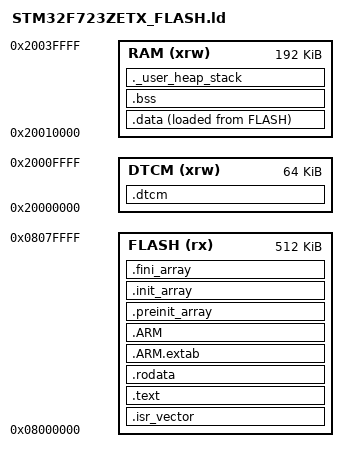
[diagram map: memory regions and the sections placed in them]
/*
******************************************************************************
**
** @file        : LinkerScript.ld
**
** @author      : Auto-generated by STM32CubeIDE
**
** @brief       : Linker script for STM32F723ZETx Device from STM32F7 series
**                      512KBytes FLASH
**                      256KBytes RAM
**
**                Set heap size, stack size and stack location according
**                to application requirements.
**
**                Set memory bank area and size if external memory is used
**
**  Target      : STMicroelectronics STM32
**
**  Distribution: The file is distributed as is, without any warranty
**                of any kind.
**
******************************************************************************
** @attention
**
** Copyright (c) 2026 STMicroelectronics.
** All rights reserved.
**
** This software is licensed under terms that can be found in the LICENSE file
** in the root directory of this software component.
** If no LICENSE file comes with this software, it is provided AS-IS.
**
******************************************************************************
*/

/* Entry Point */
ENTRY(Reset_Handler)

/* Highest address of the user mode stack */
_estack = ORIGIN(RAM) + LENGTH(RAM); /* end of "RAM" Ram type memory */

_Min_Heap_Size = 0x200;  /* required amount of heap  */
_Min_Stack_Size = 0x1000; /* required amount of stack */
/* Stack raised 0x400 -> 0x1000 (TN-16 open item 19). The console, the
   self-flasher and the coming logger all add call depth, and 1 KiB was
   already uncomfortable next to vsnprintf.

   REGENERATION HAZARD: CubeIDE rewrote this line back to 0x400 on 27 Jul 2026
   while leaving the MEMORY block and the .dtcm section intact. It templates
   the two size lines but not the rest of the script, so check this value
   after every regeneration. Added to the TN-17A section 8 checklist. */

/* Memories definition
 *
 * SPLIT FROM A SINGLE FLAT REGION, 27 July 2026. CubeMX generates one 256 KiB
 * block at 0x20000000, which silently places every .data and .bss object in
 * DTCM. Two problems follow, and both are fixed by declaring the split:
 *
 *   1. DMA. On STM32F7 the DTCM is reachable by DMA only through the CPU's
 *      AHB-slave port, and it is a well-documented source of intermittent
 *      failures. Standard practice is to keep DMA buffers in SRAM1. With one
 *      flat region a DMA buffer lands in DTCM by accident; with the split it
 *      cannot.
 *
 *   2. Execution. .RamFunc rides inside .data, so the self-flasher's
 *      erase-and-program routine was executing from DTCM. That worked, but on
 *      an inference rather than a fact (TN-17 section 3.2). It now runs from
 *      SRAM1, where the question does not arise.
 *
 * Layout on the STM32F723ZE:
 *   DTCM   0x20000000  64 KiB   tightly coupled, fastest, NOT DMA-friendly
 *   SRAM1  0x20010000 176 KiB \ contiguous, on the AHB matrix, DMA-safe
 *   SRAM2  0x2003C000  16 KiB /
 *
 * DTCM is declared but nothing is placed in it yet. Put latency-critical data
 * the DMA never touches there later; see the .dtcm section below.
 */
MEMORY
{
  DTCM   (xrw)    : ORIGIN = 0x20000000,   LENGTH = 64K
  RAM    (xrw)    : ORIGIN = 0x20010000,   LENGTH = 192K
  FLASH   (rx)    : ORIGIN = 0x08000000,   LENGTH = 512K
}

/* Sections */
SECTIONS
{

  /* The startup code into "FLASH" Rom type memory */
  .isr_vector :
  {
    . = ALIGN(4);
    KEEP(*(.isr_vector)) /* Startup code */
    . = ALIGN(4);
  } >FLASH

  /* The program code and other data into "FLASH" Rom type memory */
  .text :
  {
    . = ALIGN(4);
    *(.text)           /* .text sections (code) */
    *(.text*)          /* .text* sections (code) */
    *(.glue_7)         /* glue arm to thumb code */
    *(.glue_7t)        /* glue thumb to arm code */
    *(.eh_frame)

    KEEP (*(.init))
    KEEP (*(.fini))

    . = ALIGN(4);
    _etext = .;        /* define a global symbols at end of code */
  } >FLASH

  /* Constant data into "FLASH" Rom type memory */
  .rodata :
  {
    . = ALIGN(4);
    *(.rodata)         /* .rodata sections (constants, strings, etc.) */
    *(.rodata*)        /* .rodata* sections (constants, strings, etc.) */
    . = ALIGN(4);
  } >FLASH

  .ARM.extab (READONLY) : /* The "READONLY" keyword is only supported in GCC11 and later, remove it if using GCC10 or earlier. */
  {
    . = ALIGN(4);
    *(.ARM.extab* .gnu.linkonce.armextab.*)
    . = ALIGN(4);
  } >FLASH

  .ARM (READONLY) : /* The "READONLY" keyword is only supported in GCC11 and later, remove it if using GCC10 or earlier. */
  {
    . = ALIGN(4);
    __exidx_start = .;
    *(.ARM.exidx*)
    __exidx_end = .;
    . = ALIGN(4);
  } >FLASH

  .preinit_array (READONLY) : /* The "READONLY" keyword is only supported in GCC11 and later, remove it if using GCC10 or earlier. */
  {
    . = ALIGN(4);
    PROVIDE_HIDDEN (__preinit_array_start = .);
    KEEP (*(.preinit_array*))
    PROVIDE_HIDDEN (__preinit_array_end = .);
    . = ALIGN(4);
  } >FLASH

  .init_array (READONLY) : /* The "READONLY" keyword is only supported in GCC11 and later, remove it if using GCC10 or earlier. */
  {
    . = ALIGN(4);
    PROVIDE_HIDDEN (__init_array_start = .);
    KEEP (*(SORT(.init_array.*)))
    KEEP (*(.init_array*))
    PROVIDE_HIDDEN (__init_array_end = .);
    . = ALIGN(4);
  } >FLASH

  .fini_array (READONLY) : /* The "READONLY" keyword is only supported in GCC11 and later, remove it if using GCC10 or earlier. */
  {
    . = ALIGN(4);
    PROVIDE_HIDDEN (__fini_array_start = .);
    KEEP (*(SORT(.fini_array.*)))
    KEEP (*(.fini_array*))
    PROVIDE_HIDDEN (__fini_array_end = .);
    . = ALIGN(4);
  } >FLASH

  /* Used by the startup to initialize data */
  _sidata = LOADADDR(.data);

  /* Initialized data sections into "RAM" Ram type memory */
  .data :
  {
    . = ALIGN(4);
    _sdata = .;        /* create a global symbol at data start */
    *(.data)           /* .data sections */
    *(.data*)          /* .data* sections */
    *(.RamFunc)        /* .RamFunc sections */
    *(.RamFunc*)       /* .RamFunc* sections */

    . = ALIGN(4);
    _edata = .;        /* define a global symbol at data end */

  } >RAM AT> FLASH

  /* Uninitialized data section into "RAM" Ram type memory */
  . = ALIGN(4);
  .bss :
  {
    /* This is used by the startup in order to initialize the .bss section */
    _sbss = .;         /* define a global symbol at bss start */
    __bss_start__ = _sbss;
    *(.bss)
    *(.bss*)
    *(COMMON)

    . = ALIGN(4);
    _ebss = .;         /* define a global symbol at bss end */
    __bss_end__ = _ebss;
  } >RAM

  /* User_heap_stack section, used to check that there is enough "RAM" Ram  type memory left */
  ._user_heap_stack :
  {
    . = ALIGN(8);
    PROVIDE ( end = . );
    PROVIDE ( _end = . );
    . = . + _Min_Heap_Size;
    . = . + _Min_Stack_Size;
    . = ALIGN(8);
  } >RAM

  /* Tightly-coupled data memory. Nothing is placed here yet; the section
     exists so that later work can opt in with
         __attribute__((section(".dtcm")))
     for latency-critical data that DMA never touches. NOLOAD because DTCM
     contents are not initialised from flash. */
  .dtcm (NOLOAD) :
  {
    . = ALIGN(8);
    _sdtcm = .;
    *(.dtcm)
    *(.dtcm*)
    . = ALIGN(8);
    _edtcm = .;
  } >DTCM

  /* Remove information from the compiler libraries */
  /DISCARD/ :
  {
    libc.a ( * )
    libm.a ( * )
    libgcc.a ( * )
  }

  .ARM.attributes 0 : { *(.ARM.attributes) }
}
